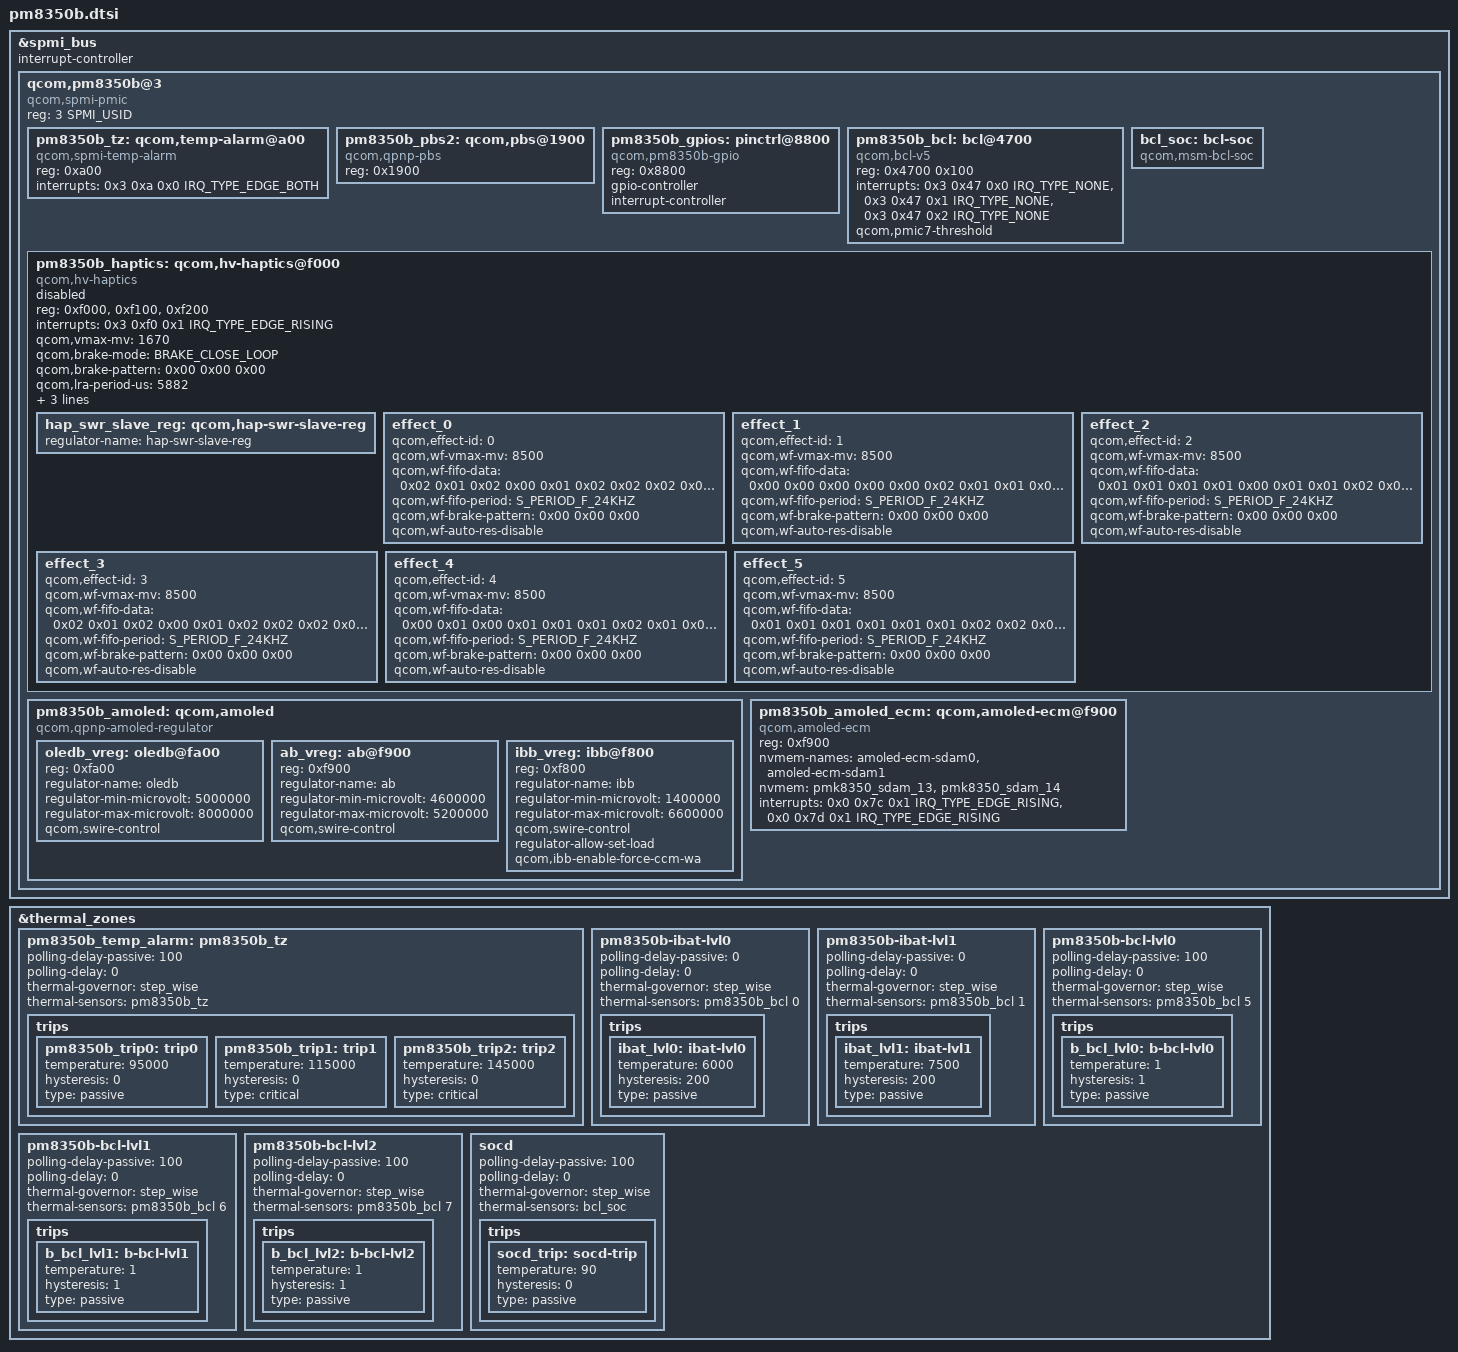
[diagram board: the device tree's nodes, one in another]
#include <dt-bindings/interrupt-controller/irq.h>
#include <dt-bindings/spmi/spmi.h>
#include <dt-bindings/input/qcom,hv-haptics.h>

&spmi_bus {
	#address-cells = <2>;
	#size-cells = <0>;
	interrupt-controller;
	#interrupt-cells = <4>;

	qcom,pm8350b@3 {
		compatible = "qcom,spmi-pmic";
		reg = <3 SPMI_USID>;
		#address-cells = <1>;
		#size-cells = <0>;

		pm8350b_tz: qcom,temp-alarm@a00 {
			compatible = "qcom,spmi-temp-alarm";
			reg = <0xa00>;
			interrupts = <0x3 0xa 0x0 IRQ_TYPE_EDGE_BOTH>;
			#thermal-sensor-cells = <0>;
		};

		pm8350b_pbs2: qcom,pbs@1900 {
			compatible = "qcom,qpnp-pbs";
			reg = <0x1900>;
		};

		pm8350b_gpios: pinctrl@8800 {
			compatible = "qcom,pm8350b-gpio";
			reg = <0x8800>;
			gpio-controller;
			#gpio-cells = <2>;
			interrupt-controller;
			#interrupt-cells = <2>;
		};

		pm8350b_bcl: bcl@4700 {
			compatible = "qcom,bcl-v5";
			reg = <0x4700 0x100>;
			interrupts = <0x3 0x47 0x0 IRQ_TYPE_NONE>,
					<0x3 0x47 0x1 IRQ_TYPE_NONE>,
					<0x3 0x47 0x2 IRQ_TYPE_NONE>;
			interrupt-names = "bcl-lvl0",
						"bcl-lvl1",
						"bcl-lvl2";
			qcom,pmic7-threshold;
			#thermal-sensor-cells = <1>;
		};

		bcl_soc:bcl-soc {
			compatible = "qcom,msm-bcl-soc";
			#thermal-sensor-cells = <0>;
		};

		pm8350b_haptics: qcom,hv-haptics@f000 {
			compatible = "qcom,hv-haptics";
			reg = <0xf000>, <0xf100>, <0xf200>;
			interrupts = <0x3 0xf0 0x1 IRQ_TYPE_EDGE_RISING>;
			interrupt-names = "fifo-empty";
			qcom,vmax-mv = <1670>;
			qcom,brake-mode = <BRAKE_CLOSE_LOOP>;
			qcom,brake-pattern = /bits/ 8 <0x00 0x00 0x00>;
			qcom,lra-period-us = <5882>;
			qcom,drv-sig-shape = <WF_SINE>;
			qcom,brake-sig-shape = <WF_SINE>;
			qcom,brake-disable = <1>;
			status = "disabled";

			hap_swr_slave_reg: qcom,hap-swr-slave-reg {
				regulator-name = "hap-swr-slave-reg";
			};

			effect_0 {
				/* CLICK */
				qcom,effect-id = <0>;
				qcom,wf-vmax-mv = <8500>;
				qcom,wf-fifo-data = /bits/ 8 <0x02 0x01 0x02 0x00 0x01 0x02 0x02 0x02 0x03 0x03 0x03 0x04 0x05 0x05 0x05 0x07
							0x07 0x07 0x09 0x0B 0x0C 0x0F 0x10 0x13 0x15 0x18 0x1B 0x1F 0x23 0x29 0x2E 0x34
							0x3C 0x43 0x4B 0x51 0x55 0x5B 0x5F 0x63 0x65 0x69 0x6A 0x6C 0x6E 0x6E 0x70 0x71
							0x71 0x72 0x72 0x72 0x70 0x71 0x71 0x6F 0x6F 0x6E 0x6E 0x6D 0x6C 0x6B 0x6A 0x69
							0x67 0x66 0x66 0x63 0x62 0x61 0x60 0x5E 0x5C 0x5B 0x59 0x57 0x56 0x53 0x51 0x4F
							0x4D 0x4A 0x47 0x43 0x40 0x3D 0x38 0x34 0x2E 0x28 0x21 0x19 0x11 0x06 0xFC 0xF0
							0xE1 0xD3 0xC8 0xBE 0xB6 0xAE 0xA8 0xA1 0x9E 0x99 0x96 0x94 0x93 0x91 0x90 0x90
							0x91 0x90 0x91 0x91 0x93 0x94 0x95 0x97 0x9A 0x9B 0x9D 0x9F 0xA3 0xA5 0xA7 0xA9
							0xAD 0xAF 0xB2 0xB4 0xB7 0xBA 0xBC 0xBF 0xC2 0xC5 0xC7 0xCA 0xCD 0xD0 0xD2 0xD6
							0xD8 0xDB 0xDE 0xE1 0xE6 0xE8 0xEB 0xEF 0xF3 0xF7 0xFB 0x01 0x06 0x0C 0x12 0x19
							0x20 0x28 0x2C 0x31 0x35 0x38 0x3A 0x3C 0x3D 0x3E 0x3F 0x3F 0x3E 0x3E 0x3C 0x3C
							0x39 0x37 0x36 0x34 0x31 0x2F 0x2C 0x29 0x26 0x23 0x20 0x1D 0x1A 0x17 0x14 0x10
							0x0D 0x09 0x07 0x04 0x00 0xFD 0xFA 0xF7 0xF5 0xF1 0xF0 0xEE 0xEA 0xE8 0xE7 0xE5
							0xE4 0xE3 0xE1 0xE1 0xE0 0xE1 0xE1 0xE2 0xE5 0xE5 0xE7 0xEA 0xEF 0xF3 0xF9 0xFF
							0x04 0x0A 0x0E 0x13 0x17 0x1B 0x1E 0x22 0x25 0x27 0x2A 0x2D 0x30 0x33 0x35 0x38
							0x3A 0x3D 0x3F 0x41 0x43 0x44 0x48 0x4B 0x4D 0x4F 0x52 0x55 0x57 0x59 0x5C 0x5E
							0x60 0x63 0x64 0x67 0x69 0x6A 0x6D 0x6E 0x6F 0x71 0x72 0x72 0x74 0x74 0x75 0x74
							0x74 0x73 0x72 0x70 0x6E 0x6D 0x68 0x65 0x60 0x5B 0x53 0x4C 0x43 0x3A 0x2D 0x21
							0x16 0x0D 0x05 0xFD 0xF6 0xF2 0xEC 0xE7 0xE3 0xDF 0xDC 0xD9 0xD6 0xD3 0xD1 0xD0
							0xCC 0xCD 0xCA 0xC8 0xC7 0xC6 0xC4 0xC3 0xC2 0xC0 0xC0 0xC0 0xBF 0xBE 0xBE 0xBC
							0xBC 0xBB 0xBB 0xBA 0xBA 0xB9 0xB8 0xB8 0xB7 0xB7 0xB7 0xB7 0xB6 0xB8 0xB7 0xB7
							0xB7 0xB9 0xB9 0xBB 0xBC 0xBD 0xBE 0xC0 0xC2 0xC5 0xC8 0xCC 0xD0 0xD5 0xDA 0xDF
							0xE3 0xE7 0xE9 0xEC 0xEF 0xF1 0xF3 0xF4 0xF5 0xF7 0xF8 0xF9 0xFB 0xFB 0xFA 0xFC
							0xFC 0xFD 0xFD 0xFE 0xFD 0xFD 0xFF 0xFE 0xFE 0xFE 0xFE 0xFE 0xFE>;
				qcom,wf-fifo-period = <S_PERIOD_F_24KHZ>;
				qcom,wf-brake-pattern = /bits/ 8 <0x00 0x00 0x00>;
				qcom,wf-auto-res-disable;
			};

			effect_1 {
				/* DOUBLE_CLICK */
				qcom,effect-id = <1>;
				qcom,wf-vmax-mv = <8500>;
				qcom,wf-fifo-data = /bits/ 8 <0x00 0x00 0x00 0x00 0x00 0x02 0x01 0x01 0x02 0x03 0x03 0x04 0x04 0x05 0x05 0x06
						0x07 0x08 0x09 0x0B 0x0C 0x0F 0x10 0x13 0x15 0x18 0x1B 0x20 0x23 0x28 0x2E 0x35
						0x3C 0x41 0x46 0x4B 0x50 0x53 0x57 0x5A 0x5D 0x5F 0x61 0x62 0x64 0x65 0x66 0x68
						0x69 0x6A 0x6B 0x6A 0x6B 0x6D 0x6C 0x6D 0x6D 0x6E 0x6D 0x6E 0x6E 0x6F 0x6F 0x6E
						0x6F 0x70 0x6F 0x70 0x70 0x6F 0x6F 0x6F 0x6E 0x6D 0x6E 0x6E 0x6E 0x6E 0x6C 0x6B
						0x6B 0x69 0x69 0x67 0x65 0x65 0x62 0x60 0x5C 0x5A 0x58 0x54 0x4F 0x4B 0x44 0x40
						0x38 0x30 0x26 0x1C 0x10 0x03 0xF5 0xE9 0xDF 0xD6 0xCF 0xC7 0xC1 0xBC 0xB7 0xB3
						0xAF 0xAC 0xAA 0xA6 0xA4 0xA2 0xA0 0x9F 0x9E 0x9C 0x9B 0x99 0x98 0x97 0x96 0x97
						0x96 0x95 0x93 0x93 0x93 0x92 0x92 0x93 0x92 0x91 0x92 0x92 0x91 0x90 0x90 0x90
						0x90 0x90 0x90 0x90 0x90 0x92 0x91 0x91 0x93 0x92 0x93 0x94 0x96 0x97 0x99 0x9A
						0x9C 0x9E 0xA0 0xA4 0xA6 0xAB 0xB0 0xB4 0xBA 0xC0 0xC8 0xCF 0xD6 0xDC 0xE3 0xE8
						0xEB 0xF0 0xF2 0xF6 0xF9 0xFA 0xFD 0xFF 0x00 0x03 0x04 0x05 0x06 0x07 0x08 0x08
						0x0A 0x0A 0x0C 0x0B 0x0D 0x0C 0x0E 0x0E 0x0F 0x0E 0x10 0x11 0x11 0x12 0x12 0x13
						0x13 0x13 0x14 0x15 0x16 0x16 0x16 0x17 0x18 0x17 0x18 0x19 0x1B 0x1B 0x1B 0x1D
						0x1E 0x1F 0x20 0x21 0x22 0x24 0x26 0x28 0x2A 0x2C 0x2F 0x33 0x36 0x3A 0x3F 0x43
						0x49 0x4E 0x52 0x57 0x5A 0x5D 0x60 0x63 0x65 0x66 0x69 0x68 0x6B 0x6B 0x6C 0x6C
						0x6E 0x6D 0x6F 0x6F 0x6E 0x6F 0x6F 0x6E 0x6F 0x6F 0x6F 0x6F 0x70 0x6E 0x6E 0x6F
						0x6E 0x6E 0x6E 0x6D 0x6C 0x6D 0x6C 0x6B 0x6B 0x6B 0x6B 0x6A 0x69 0x68 0x67 0x66
						0x65 0x65 0x64 0x62 0x60 0x5F 0x5E 0x5B 0x59 0x56 0x53 0x50 0x4D 0x49 0x43 0x40
						0x39 0x32 0x2A 0x22 0x17 0x0C 0x01 0xF7 0xEE 0xE6 0xDF 0xD9 0xD4 0xCF 0xCC 0xC8
						0xC4 0xC2 0xC0 0xBE 0xBD 0xBB 0xBA 0xB8 0xB8 0xB7 0xB6 0xB5 0xB5 0xB5 0xB3 0xB3
						0xB2 0xB3 0xB3 0xB2 0xB2 0xB1 0xB2 0xB2 0xB2 0xB2 0xB1 0xB1 0xB2 0xB1 0xB2 0xB3
						0xB2 0xB2 0xB2 0xB4 0xB3 0xB4 0xB4 0xB5 0xB5 0xB7 0xB6 0xB6 0xB7 0xB8 0xBA 0xBB
						0xBD 0xBD 0xBF 0xC0 0xC2 0xC5 0xC7 0xCA 0xCE 0xD1 0xD6 0xDB 0xDF 0xE2 0xE6 0xE8
						0xEB 0xEE 0xF1 0xF1 0xF3 0xF5 0xF7 0xF8 0xF7 0xFA 0xFB 0xFB 0xFB 0xFC 0xFD 0xFC
						0xFE 0xFD 0xFE 0xFE 0xFE 0xFF 0xFF 0xFF 0xFF 0xFF 0xFF 0x00 0x01 0x00 0x00 0x00
						0x00 0x00 0x00 0x00 0x01 0x00 0x01 0x02 0x01 0x01 0x01 0x01 0x00 0x00 0x00 0x01
						0x01 0x00 0x01 0x01 0x00 0x01 0x00 0x01 0x01 0x01 0x01>;
				qcom,wf-fifo-period = <S_PERIOD_F_24KHZ>;
				qcom,wf-brake-pattern = /bits/ 8 <0x00 0x00 0x00>;
				qcom,wf-auto-res-disable;
			};

			effect_2 {
				/* TICK */
				qcom,effect-id = <2>;
				qcom,wf-vmax-mv = <8500>;
				qcom,wf-fifo-data = /bits/ 8 <0x01 0x01 0x01 0x01 0x00 0x01 0x01 0x02 0x01 0x03 0x02 0x04 0x04 0x05 0x05 0x05
						0x07 0x07 0x09 0x0A 0x0D 0x0D 0x0F 0x11 0x13 0x17 0x19 0x1D 0x22 0x26 0x2A 0x31
						0x38 0x3F 0x45 0x4B 0x50 0x56 0x59 0x5B 0x5D 0x61 0x62 0x63 0x64 0x64 0x63 0x65
						0x64 0x63 0x63 0x61 0x60 0x61 0x5E 0x5C 0x5B 0x59 0x57 0x56 0x54 0x51 0x50 0x4E
						0x4C 0x49 0x47 0x43 0x42 0x40 0x3D 0x3A 0x37 0x36 0x31 0x2F 0x2B 0x28 0x24 0x20
						0x1A 0x15 0x11 0x0C 0x06 0xFF 0xF7 0xEE 0xE5 0xDB 0xCF 0xC3 0xB9 0xAF 0xA7 0xA0
						0x9C 0x98 0x94 0x92 0x90 0x8F 0x8F 0x90 0x90 0x91 0x94 0x96 0x98 0x9C 0x9F 0xA2
						0xA6 0xAB 0xAD 0xB3 0xB6 0xBC 0xC0 0xC4 0xC8 0xCD 0xD1 0xD6 0xDB 0xE0 0xE4 0xE8
						0xED 0xF0 0xF5 0xF8 0xFC 0x00 0x04 0x06 0x09 0x0C 0x0D 0x0F 0x12 0x13 0x15 0x16
						0x16 0x15 0x15 0x14 0x12 0x11 0x0F 0x0F 0x0C 0x0B 0x08 0x06 0x04 0x02 0xFF 0xFC
						0xF9 0xF6 0xF3 0xF0 0xEC 0xE9 0xE6 0xE2 0xDD 0xD9 0xD5 0xD1 0xCD 0xC9 0xC5 0xC1
						0xBD 0xB9 0xB5 0xB2 0xAC 0xA9 0xA6 0xA2 0x9F 0x9C 0x99 0x95 0x94 0x91 0x8F 0x8E
						0x8D 0x8C 0x8D 0x8D 0x8C 0x90 0x90 0x93 0x97 0x9E 0xA4 0xA9 0xB2 0xBC 0xC7 0xD1
						0xDB 0xE2 0xEA 0xEF 0xF7 0xFC 0x01 0x05 0x08 0x0C 0x10 0x12 0x16 0x18 0x1A 0x1C
						0x1E 0x20 0x23 0x25 0x26 0x29 0x2B 0x2C 0x2E 0x2F 0x31 0x31 0x33 0x34 0x35 0x37
						0x38 0x39 0x3A 0x3C 0x3B 0x3D 0x3E 0x3E 0x3E 0x3E 0x3E 0x3E 0x3D 0x3D 0x3D 0x3B
						0x3A 0x38 0x36 0x34 0x31 0x2F 0x2A 0x26 0x21 0x1E 0x1A 0x16 0x14 0x11 0x0F 0x0E
						0x0B 0x0A 0x0A 0x08 0x07 0x06 0x05 0x05 0x03 0x04 0x03 0x03 0x03 0x02 0x02 0x02
						0x02 0x01 0x00 0x01 0x02 0x01 0x01 0x00 0x01 0x01 0x01 0x00 0x01 0x00 0x01 0x01>;
				qcom,wf-fifo-period = <S_PERIOD_F_24KHZ>;
				qcom,wf-brake-pattern = /bits/ 8 <0x00 0x00 0x00>;
				qcom,wf-auto-res-disable;
			};

			effect_3 {
				/* THUD */
				qcom,effect-id = <3>;
				qcom,wf-vmax-mv = <8500>;
				qcom,wf-fifo-data = /bits/ 8 <0x02 0x01 0x02 0x00 0x01 0x02 0x02 0x02 0x03 0x03 0x03 0x04 0x05 0x05 0x05 0x07
						0x07 0x07 0x09 0x0B 0x0C 0x0F 0x10 0x12 0x15 0x18 0x1B 0x1F 0x24 0x29 0x2F 0x35
						0x3C 0x42 0x48 0x4D 0x50 0x53 0x56 0x57 0x57 0x59 0x57 0x58 0x58 0x55 0x54 0x53
						0x50 0x4F 0x4C 0x49 0x45 0x42 0x40 0x3B 0x39 0x34 0x31 0x2D 0x28 0x24 0x20 0x1C
						0x17 0x13 0x0F 0x08 0x04 0xFF 0xFA 0xF5 0xEF 0xE9 0xE3 0xDB 0xD5 0xCC 0xC4 0xBA
						0xB0 0xA4 0x9B 0x94 0x8E 0x8A 0x87 0x87 0x86 0x86 0x88 0x8A 0x8E 0x90 0x96 0x9B
						0xA0 0xA6 0xAE 0xB4 0xBD 0xC2 0xCB 0xD2 0xDB 0xE3 0xEC 0xF3 0xFC 0x04 0x0B 0x13
						0x1C 0x22 0x29 0x2F 0x35 0x3B 0x40 0x44 0x48 0x4C 0x4E 0x50 0x53 0x54 0x54 0x53
						0x53 0x50 0x4E 0x4A 0x48 0x46 0x41 0x3F 0x3B 0x37 0x31 0x2D 0x27 0x21 0x1C 0x16
						0x0E 0x08 0x02 0xFB 0xF4 0xED 0xE6 0xDE 0xD7 0xD0 0xC9 0xC3 0xBD 0xB6 0xB0 0xAA
						0xA4 0x9F 0x9A 0x95 0x92 0x8F 0x8B 0x89 0x89 0x89 0x8A 0x8B 0x8E 0x92 0x98 0x9E
						0xA5 0xAF 0xBA 0xC2 0xCA 0xD2 0xD8 0xDE 0xE3 0xE8 0xED 0xF1 0xF5 0xFA 0xFE 0x01
						0x03 0x07 0x0A 0x0E 0x10 0x13 0x16 0x19 0x1B 0x1D 0x21 0x23 0x25 0x26 0x29 0x2B
						0x2C 0x2E 0x2F 0x31 0x32 0x33 0x33 0x34 0x35 0x33 0x33 0x32 0x32 0x2F 0x2D 0x2A
						0x27 0x23 0x1F 0x1B 0x17 0x14 0x11 0x10 0x0E 0x0A 0x0A 0x09 0x08 0x07 0x05 0x04
						0x04 0x04 0x03 0x02 0x02 0x01 0x01 0x01 0x01 0x01 0x01 0x01>;
				qcom,wf-fifo-period = <S_PERIOD_F_24KHZ>;
				qcom,wf-brake-pattern = /bits/ 8 <0x00 0x00 0x00>;
				qcom,wf-auto-res-disable;
			};

			effect_4 {
				/* POP */
				qcom,effect-id = <4>;
				qcom,wf-vmax-mv = <8500>;
				qcom,wf-fifo-data = /bits/ 8 <0x00 0x01 0x00 0x01 0x01 0x01 0x02 0x01 0x03 0x03 0x03 0x05 0x05 0x05 0x05 0x06
						0x09 0x09 0x0A 0x0C 0x0D 0x0F 0x11 0x13 0x15 0x17 0x19 0x1A 0x1C 0x1D 0x1D 0x1F
						0x20 0x21 0x22 0x23 0x24 0x25 0x26 0x27 0x28 0x29 0x29 0x2A 0x2B 0x2C 0x2D 0x2E
						0x30 0x30 0x31 0x32 0x33 0x34 0x35 0x36 0x37 0x38 0x3B 0x3B 0x3C 0x3C 0x3F 0x3F
						0x40 0x41 0x42 0x44 0x45 0x46 0x47 0x48 0x4A 0x4C 0x4B 0x4E 0x4F 0x51 0x51 0x53
						0x54 0x56 0x56 0x58 0x59 0x5A 0x5C 0x5D 0x5E 0x5F 0x61 0x62 0x62 0x63 0x64 0x66
						0x67 0x68 0x69 0x69 0x6A 0x6C 0x6C 0x6E 0x6E 0x6E 0x6F 0x6F 0x71 0x70 0x72 0x72
						0x73 0x73 0x72 0x73 0x72 0x73 0x73 0x72 0x72 0x72 0x71 0x70 0x6F 0x6E 0x6D 0x6C
						0x6A 0x67 0x63 0x62 0x5F 0x5C 0x5B 0x59 0x57 0x56 0x54 0x52 0x51 0x50 0x4E 0x4C
						0x4C 0x49 0x47 0x46 0x44 0x44 0x41 0x40 0x3E 0x3D 0x3B 0x38 0x36 0x35 0x33 0x2F
						0x2E 0x2B 0x2A 0x27 0x26 0x22 0x21 0x1D 0x1B 0x18 0x17 0x14 0x12 0x10 0x0C 0x09
						0x07 0x04 0x01 0xFF 0xFC 0xF8 0xF6 0xF4 0xF1 0xEE 0xEC 0xEA 0xE7 0xE4 0xE1 0xDF
						0xDD 0xDA 0xD7 0xD4 0xD2 0xCF 0xCD 0xCB 0xC8 0xC6 0xC3 0xC2 0xC0 0xBE 0xBC 0xBA
						0xB9 0xB7 0xB4 0xB2 0xB0 0xAF 0xAD 0xAC 0xAB 0xA9 0xA8 0xA6 0xA6 0xA3 0xA3 0xA1
						0xA1 0xA0 0x9E 0x9F 0x9E 0x9D 0x9D 0x9D 0x9D 0x9C 0x9E 0x9E 0x9E 0x9E 0xA0 0x9F
						0xA0 0xA2 0xA3 0xA3 0xA4 0xA5 0xA6 0xA6 0xA8 0xA8 0xAA 0xAB 0xAC 0xAF 0xAF 0xB2
						0xB3 0xB4 0xB5 0xB7 0xBA 0xBB 0xBD 0xBE 0xC0 0xC2 0xC4 0xC6 0xC9 0xCB 0xCD 0xCF
						0xD2 0xD5 0xD7 0xD9 0xDC 0xDE 0xE2 0xE4 0xE7 0xEA 0xEC 0xEF 0xF2 0xF4 0xF7 0xFB
						0xFD 0xFF 0x03 0x05 0x08 0x0A 0x0D 0x10 0x13 0x17 0x19 0x1B 0x1F 0x22 0x24 0x26
						0x28 0x2B 0x2E 0x31 0x33 0x34 0x38 0x3A 0x3C 0x3F 0x40 0x42 0x44 0x45 0x48 0x49
						0x4B 0x4D 0x4F 0x51 0x52 0x54 0x55 0x55 0x58 0x58 0x5A 0x5B 0x5B 0x5C 0x5D 0x5E
						0x5F 0x5F 0x5F 0x60 0x60 0x60 0x60 0x5F 0x5F 0x5F 0x5E 0x5E 0x5E 0x5C 0x5C 0x5B
						0x5A 0x5A 0x59 0x58 0x57 0x56 0x53 0x53 0x51 0x51 0x4E 0x4E 0x4C 0x49 0x49 0x46
						0x44 0x44 0x42 0x40 0x3D 0x3C 0x3A 0x38 0x35 0x33 0x31 0x2E 0x2C 0x29 0x27 0x24
						0x21 0x1F 0x1C 0x19 0x17 0x13 0x11 0x0E 0x0B 0x09 0x06 0x03 0x00 0xFE 0xFC 0xF8
						0xF5 0xF2 0xEF 0xEC 0xEB 0xE7 0xE5 0xE2 0xDF 0xDD 0xDA 0xD7 0xD5 0xD2 0xD0 0xCD
						0xCA 0xC8 0xC6 0xC3 0xC1 0xC0 0xBE 0xBC 0xB9 0xB8 0xB7 0xB4 0xB3 0xB0 0xAE 0xAE
						0xAC 0xAA 0xA9 0xA7 0xA6 0xA3 0xA3 0xA1 0xA0 0xA0 0x9F 0x9C 0x9C 0x9B 0x9A 0x99
						0x99 0x98 0x97 0x96 0x95 0x94 0x93 0x92 0x92 0x91 0x91 0x91 0x91 0x90 0x92 0x91
						0x93 0x93 0x93 0x94 0x95 0x96 0x97 0x98 0x99 0x99 0x9B 0x9C 0x9D 0x9E 0xA0 0xA2
						0xA3 0xA4 0xA5 0xA7 0xA8 0xAA 0xAC 0xAE 0xB0 0xB2 0xB4 0xB5 0xB6 0xB9 0xBA 0xBC
						0xBF 0xC0 0xC1 0xC4 0xC5 0xC8 0xCA 0xCB 0xCC 0xCF 0xD1 0xD3 0xD5 0xD6 0xD9 0xDA
						0xDD 0xDF 0xE0 0xE2 0xE4 0xE6 0xE8 0xE9 0xEB 0xEC 0xEE 0xF0 0xF2 0xF4 0xF6 0xF7
						0xF9 0xFA 0xFC 0xFD 0xFF 0xFF 0x01 0x03 0x05 0x05 0x07 0x09 0x09 0x0A 0x0B 0x0C
						0x0D 0x0F 0x10 0x12 0x12 0x13 0x15 0x15 0x16 0x18 0x1A 0x1B 0x1B 0x1E 0x20 0x22
						0x24 0x26 0x28 0x29 0x2B 0x2B 0x2C 0x2D 0x2D 0x2F 0x2E 0x2F 0x30 0x30 0x2F 0x2F
						0x30 0x2F 0x2F 0x2F 0x2F 0x2F 0x2F 0x2E 0x2F 0x2E 0x2E 0x2D 0x2D 0x2C 0x2D 0x2B
						0x2C 0x2B 0x2B 0x2A 0x2B 0x29 0x29 0x28 0x27 0x27 0x26 0x26 0x26 0x24 0x25 0x23
						0x24 0x23 0x22 0x21 0x21 0x21 0x20 0x1E 0x1F 0x1E 0x1E 0x1D 0x1D 0x1C 0x1B 0x1C
						0x1B 0x1A 0x19 0x18 0x19 0x18 0x18 0x17 0x18 0x17 0x16 0x15 0x15 0x14 0x14 0x13
						0x13 0x12 0x12 0x12 0x11 0x11 0x10 0x11 0x10 0x0F 0x0F 0x0E 0x0F 0x0F 0x0E 0x0D
						0x0C 0x0C 0x0C 0x0B 0x0A 0x0B 0x09 0x0A 0x08 0x08 0x07 0x05 0x06 0x04 0x04 0x04
						0x02 0x03 0x02 0x02 0x02 0x01 0x01 0x01 0x01>;
				qcom,wf-fifo-period = <S_PERIOD_F_24KHZ>;
				qcom,wf-brake-pattern = /bits/ 8 <0x00 0x00 0x00>;
				qcom,wf-auto-res-disable;
			};

			effect_5 {
				/* HEAVY CLICK */
				qcom,effect-id = <5>;
				qcom,wf-vmax-mv = <8500>;
				qcom,wf-fifo-data = /bits/ 8 <0x01 0x01 0x01 0x01 0x01 0x01 0x02 0x02 0x02 0x03 0x03 0x04 0x04 0x05 0x06 0x07
						0x08 0x09 0x0A 0x0C 0x0D 0x0E 0x11 0x13 0x16 0x19 0x1D 0x21 0x26 0x2A 0x30 0x35
						0x3A 0x3D 0x3F 0x40 0x40 0x40 0x40 0x3F 0x3D 0x3A 0x38 0x34 0x31 0x2D 0x29 0x25
						0x21 0x1C 0x17 0x12 0x0D 0x08 0x03 0xFD 0xF8 0xF3 0xEE 0xE9 0xE4 0xDE 0xDA 0xD4
						0xCF 0xC9 0xC3 0xBD 0xB7 0xB0 0xAB 0xA8 0xA6 0xA6 0xA6 0xA8 0xAB 0xAF 0xB4 0xBA
						0xC0 0xC6 0xCE 0xD6 0xDE 0xE7 0xF1 0xF9 0x03 0x0D 0x16 0x1F 0x28 0x31 0x3A 0x42
						0x4A 0x51 0x59 0x5E 0x64 0x6A 0x6E 0x72 0x75 0x77 0x79 0x7A 0x7A 0x7A 0x78 0x75
						0x73 0x6F 0x6A 0x64 0x5D 0x57 0x4F 0x46 0x3E 0x35 0x2B 0x22 0x18 0x0E 0x04 0xFA
						0xF1 0xE7 0xDD 0xD4 0xCB 0xC3 0xBC 0xB4 0xAD 0xA8 0xA4 0x9F 0x9C 0x9A 0x99 0x99
						0x9B 0x9E 0xA2 0xA6 0xA9 0xAD 0xB2 0xB7 0xBC 0xC1 0xC6 0xCD 0xD3 0xDA 0xE0 0xE7
						0xEE 0xF4 0xFC 0x03 0x0B 0x11 0x18 0x20 0x26 0x2C 0x32 0x38 0x3D 0x41 0x45 0x48
						0x4B 0x4C 0x4D 0x4D 0x4C 0x4A 0x46 0x41 0x3C 0x36 0x30 0x2B 0x26 0x23 0x1E 0x1A
						0x17 0x13 0x10 0x0D 0x0A 0x07 0x04 0x01 0xFE 0xFB 0xF9 0xF6 0xF3 0xF2 0xF0 0xED
						0xEB 0xEA 0xE8 0xE6 0xE5 0xE4 0xE3 0xE3 0xE3 0xE3 0xE4 0xE4 0xE6 0xE8 0xEA 0xED
						0xEF 0xF1 0xF3 0xF4 0xF5 0xF7 0xF8 0xF9 0xFA 0xFA 0xFB 0xFC 0xFC 0xFD 0xFD 0xFD
						0xFE 0xFE 0xFE>;
				qcom,wf-fifo-period = <S_PERIOD_F_24KHZ>;
				qcom,wf-brake-pattern = /bits/ 8 <0x00 0x00 0x00>;
				qcom,wf-auto-res-disable;
			};
		};

		pm8350b_amoled: qcom,amoled {
			compatible = "qcom,qpnp-amoled-regulator";
			#address-cells = <1>;
			#size-cells = <0>;

			oledb_vreg: oledb@fa00 {
				reg = <0xfa00>;
				reg-names = "oledb_base";
				regulator-name = "oledb";
				regulator-min-microvolt = <5000000>;
				regulator-max-microvolt = <8000000>;
				qcom,swire-control;
			};

			ab_vreg: ab@f900 {
				reg = <0xf900>;
				reg-names = "ab_base";
				regulator-name = "ab";
				regulator-min-microvolt = <4600000>;
				regulator-max-microvolt = <5200000>;
				qcom,swire-control;
			};

			ibb_vreg: ibb@f800 {
				reg = <0xf800>;
				reg-names = "ibb_base";
				regulator-name = "ibb";
				regulator-min-microvolt = <1400000>;
				regulator-max-microvolt = <6600000>;
				qcom,swire-control;
				regulator-allow-set-load;
				qcom,ibb-enable-force-ccm-wa;
			};
		};

		pm8350b_amoled_ecm: qcom,amoled-ecm@f900 {
			compatible = "qcom,amoled-ecm";
			reg = <0xf900>;
			nvmem-names = "amoled-ecm-sdam0", "amoled-ecm-sdam1";
			nvmem = <&pmk8350_sdam_13>, <&pmk8350_sdam_14>;
			interrupt-names = "ecm-sdam0", "ecm-sdam1";
			interrupts = <0x0 0x7c 0x1 IRQ_TYPE_EDGE_RISING>,
				     <0x0 0x7d 0x1 IRQ_TYPE_EDGE_RISING>;
		};
	};
};

&thermal_zones {
	pm8350b_temp_alarm: pm8350b_tz {
		polling-delay-passive = <100>;
		polling-delay = <0>;
		thermal-governor = "step_wise";
		thermal-sensors = <&pm8350b_tz>;

		trips {
			pm8350b_trip0: trip0 {
				temperature = <95000>;
				hysteresis = <0>;
				type = "passive";
			};

			pm8350b_trip1: trip1 {
				temperature = <115000>;
				hysteresis = <0>;
				type = "critical";
			};

			pm8350b_trip2: trip2 {
				temperature = <145000>;
				hysteresis = <0>;
				type = "critical";
			};
		};
	};

	pm8350b-ibat-lvl0 {
		polling-delay-passive = <0>;
		polling-delay = <0>;
		thermal-governor = "step_wise";
		thermal-sensors = <&pm8350b_bcl 0>;

		trips {
			ibat_lvl0:ibat-lvl0 {
				temperature = <6000>;
				hysteresis = <200>;
				type = "passive";
			};
		};
	};

	pm8350b-ibat-lvl1 {
		polling-delay-passive = <0>;
		polling-delay = <0>;
		thermal-governor = "step_wise";
		thermal-sensors = <&pm8350b_bcl 1>;

		trips {
			ibat_lvl1:ibat-lvl1 {
				temperature = <7500>;
				hysteresis = <200>;
				type = "passive";
			};
		};
	};

	pm8350b-bcl-lvl0 {
		polling-delay-passive = <100>;
		polling-delay = <0>;
		thermal-governor = "step_wise";
		thermal-sensors = <&pm8350b_bcl 5>;

		trips {
			b_bcl_lvl0: b-bcl-lvl0 {
				temperature = <1>;
				hysteresis = <1>;
				type = "passive";
			};
		};
	};

	pm8350b-bcl-lvl1 {
		polling-delay-passive = <100>;
		polling-delay = <0>;
		thermal-governor = "step_wise";
		thermal-sensors = <&pm8350b_bcl 6>;

		trips {
			b_bcl_lvl1: b-bcl-lvl1 {
				temperature = <1>;
				hysteresis = <1>;
				type = "passive";
			};
		};
	};

	pm8350b-bcl-lvl2 {
		polling-delay-passive = <100>;
		polling-delay = <0>;
		thermal-governor = "step_wise";
		thermal-sensors = <&pm8350b_bcl 7>;

		trips {
			b_bcl_lvl2: b-bcl-lvl2 {
				temperature = <1>;
				hysteresis = <1>;
				type = "passive";
			};
		};
	};

	socd {
		polling-delay-passive = <100>;
		polling-delay = <0>;
		thermal-governor = "step_wise";
		thermal-sensors = <&bcl_soc>;

		trips {
			socd_trip:socd-trip {
				temperature = <90>;
				hysteresis = <0>;
				type = "passive";
			};
		};
	};
};
